# nrf9220_cellrf register map
Vendor: Nordic Semiconductor; Series: nRF92; File version: 1
CPU: CM0 r0p0, little endian, no MPU, no FPU, 2 interrupt priority bits, 33 interrupts
Registers are 32-bit, read-write, reset 0x0 unless marked. A register's access mark holds for its fields unless they carry their own. Offsets are from the block's base; [hi:lo] are bit positions; {n}, {i} and the like mark numbered series; 'fields as' and 'values as' point back to an identical list.

## SX (part 3 of 3) — Ahma SX register map SX register map
Base 0x46147000
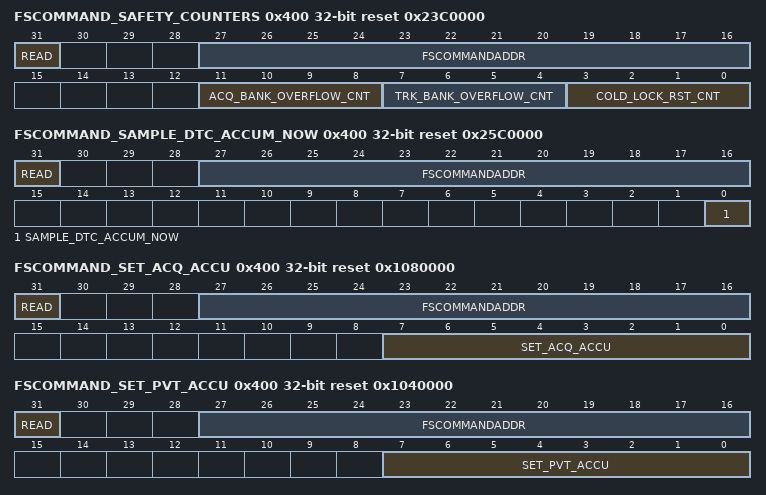
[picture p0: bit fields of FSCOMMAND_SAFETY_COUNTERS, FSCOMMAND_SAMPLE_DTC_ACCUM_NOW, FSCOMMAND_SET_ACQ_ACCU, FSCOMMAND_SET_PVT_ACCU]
0x400 FSCOMMAND_SAFETY_COUNTERS reset 0x23C0000 (alternate view of FSCOMMAND_ANA_ISOLATION) — Send or receive command directly to/from the AdPllLte digital island. Only write to this register when FSASYNCBUSBUSY returns 0
  [31] READ — When 1, a read transaction is initiated. When the event COMPLETETRANS is set, read back this register
  [27:16] FSCOMMANDADDR — Address for the async interface. ALWAYS 0x23C.
    0x23C=SAFETY_COUNTERS_ADDR (ALWAYS 0x23C.)
  [11:8] ACQ_BANK_OVERFLOW_CNT — Number of times there has been ACQ bank overflow since last starting the PLL. Max 15
  [7:4] TRK_BANK_OVERFLOW_CNT — Number of times there has been TRK bank overflow since last starting the PLL. Max 15
  [3:0] COLD_LOCK_RST_CNT — Number of times the cold lock reset safety mechanism has triggered since last starting the PLL. Max 15
0x400 FSCOMMAND_SAMPLE_DTC_ACCUM_NOW reset 0x25C0000 (alternate view of FSCOMMAND_ANA_ISOLATION) — Send or receive command directly to/from the AdPllLte digital island. Only write to this register when FSASYNCBUSBUSY returns 0
  [31] READ — When 1, a read transaction is initiated. When the event COMPLETETRANS is set, read back this register
  [27:16] FSCOMMANDADDR — Address for the async interface. ALWAYS 0x25C.
    0x25C=SAMPLE_DTC_ACCUM_NOW_ADDR (ALWAYS 0x25C.)
  [0] SAMPLE_DTC_ACCUM_NOW — Store the DTC accumulator value now
0x400 FSCOMMAND_SET_ACQ_ACCU reset 0x1080000 (alternate view of FSCOMMAND_ANA_ISOLATION) — Send or receive command directly to/from the AdPllLte digital island. Only write to this register when FSASYNCBUSBUSY returns 0
  [31] READ — When 1, a read transaction is initiated. When the event COMPLETETRANS is set, read back this register
  [27:16] FSCOMMANDADDR — Address for the async interface. ALWAYS 0x108.
    0x108=SET_ACQ_ACCU_ADDR (ALWAYS 0x108.)
  [7:0] SET_ACQ_ACCU — Writing to this register will fill in the ACQ accumulator such that the ACQ control word becomes this value. normAcqMem must be subtracted first
0x400 FSCOMMAND_SET_PVT_ACCU reset 0x1040000 (alternate view of FSCOMMAND_ANA_ISOLATION) — Send or receive command directly to/from the AdPllLte digital island. Only write to this register when FSASYNCBUSBUSY returns 0
  [31] READ — When 1, a read transaction is initiated. When the event COMPLETETRANS is set, read back this register
  [27:16] FSCOMMANDADDR — Address for the async interface. ALWAYS 0x104.
    0x104=SET_PVT_ACCU_ADDR (ALWAYS 0x104.)
  [7:0] SET_PVT_ACCU — Writing to this register will fill in the PVT accumulator such that the PVT control word becomes this value. normPvtMem must be subtracted first
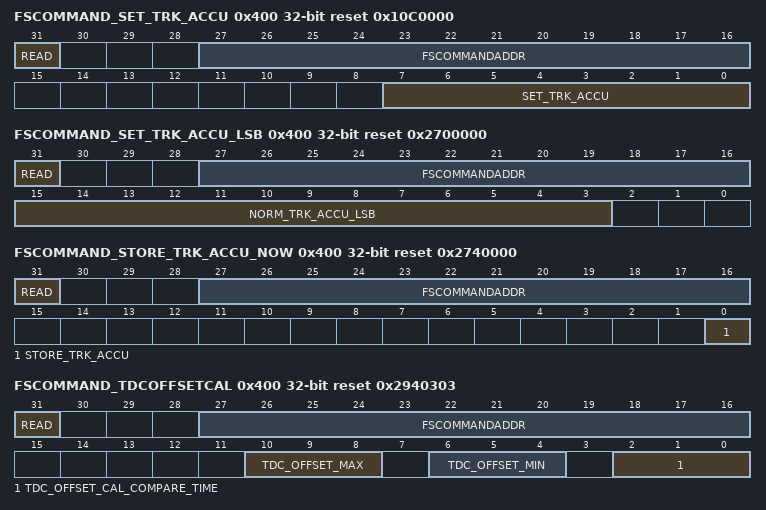
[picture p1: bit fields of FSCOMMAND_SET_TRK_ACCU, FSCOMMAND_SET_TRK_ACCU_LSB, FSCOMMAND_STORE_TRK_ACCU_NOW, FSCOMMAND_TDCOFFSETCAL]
0x400 FSCOMMAND_SET_TRK_ACCU reset 0x10C0000 (alternate view of FSCOMMAND_ANA_ISOLATION) — Send or receive command directly to/from the AdPllLte digital island. Only write to this register when FSASYNCBUSBUSY returns 0
  [31] READ — When 1, a read transaction is initiated. When the event COMPLETETRANS is set, read back this register
  [27:16] FSCOMMANDADDR — Address for the async interface. ALWAYS 0x10C.
    0x10C=SET_TRK_ACCU_ADDR (ALWAYS 0x10C.)
  [7:0] SET_TRK_ACCU — Writing to this register will fill in the TRK accumulator such that the TRK control word becomes this value. normTrkMem must be subtracted first
0x400 FSCOMMAND_SET_TRK_ACCU_LSB reset 0x2700000 (alternate view of FSCOMMAND_ANA_ISOLATION) — Send or receive command directly to/from the AdPllLte digital island. Only write to this register when FSASYNCBUSBUSY returns 0
  [31] READ — When 1, a read transaction is initiated. When the event COMPLETETRANS is set, read back this register
  [27:16] FSCOMMANDADDR — Address for the async interface. ALWAYS 0x270.
    0x270=SET_TRK_ACCU_LSB_ADDR (ALWAYS 0x270.)
  [15:3] NORM_TRK_ACCU_LSB — Sets the LSB in the TRK bank accumulator when explicitly reloading new value
0x400 FSCOMMAND_STORE_TRK_ACCU_NOW reset 0x2740000 (alternate view of FSCOMMAND_ANA_ISOLATION) — Send or receive command directly to/from the AdPllLte digital island. Only write to this register when FSASYNCBUSBUSY returns 0
  [31] READ — When 1, a read transaction is initiated. When the event COMPLETETRANS is set, read back this register
  [27:16] FSCOMMANDADDR — Address for the async interface. ALWAYS 0x274.
    0x274=STORE_TRK_ACCU_NOW_ADDR (ALWAYS 0x274.)
  [0] STORE_TRK_ACCU — Store the full accumulator value in the TRK bank loop filter control
0x400 FSCOMMAND_TDCOFFSETCAL reset 0x2940303 (alternate view of FSCOMMAND_ANA_ISOLATION) — Send or receive command directly to/from the AdPllLte digital island. Only write to this register when FSASYNCBUSBUSY returns 0
  [31] READ — When 1, a read transaction is initiated. When the event COMPLETETRANS is set, read back this register
  [27:16] FSCOMMANDADDR — Address for the async interface. ALWAYS 0x294.
    0x294=TDCOFFSETCAL_ADDR (ALWAYS 0x294.)
  [10:8] TDC_OFFSET_MAX — The maximum TDC offset value for calibration
  [6:4] TDC_OFFSET_MIN — The minimum TDC offset value for calibration
  [2:0] TDC_OFFSET_CAL_COMPARE_TIME — The time to spend on each calibration step in the TDC offset calibration algorithm. Multiply by 32 to get number of clock cycles
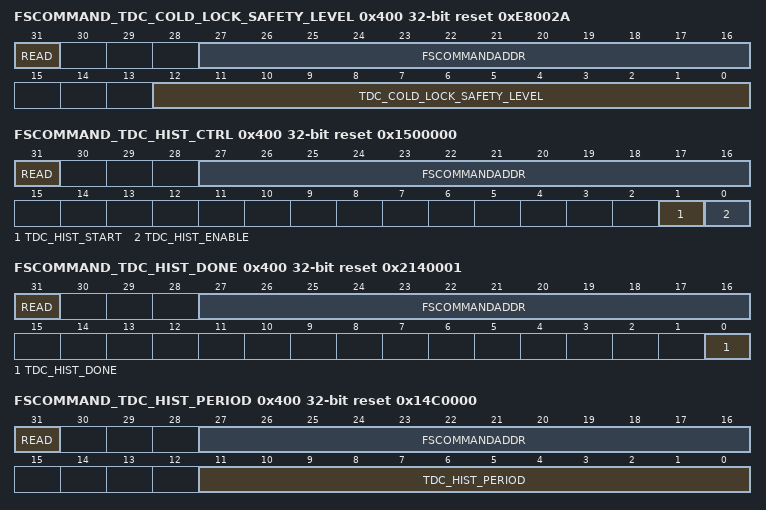
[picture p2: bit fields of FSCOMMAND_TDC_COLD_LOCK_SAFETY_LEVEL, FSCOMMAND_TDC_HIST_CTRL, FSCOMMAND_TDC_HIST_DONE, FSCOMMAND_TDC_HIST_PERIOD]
0x400 FSCOMMAND_TDC_COLD_LOCK_SAFETY_LEVEL reset 0xE8002A (alternate view of FSCOMMAND_ANA_ISOLATION) — Send or receive command directly to/from the AdPllLte digital island. Only write to this register when FSASYNCBUSBUSY returns 0
  [31] READ — When 1, a read transaction is initiated. When the event COMPLETETRANS is set, read back this register
  [27:16] FSCOMMANDADDR — Address for the async interface. ALWAYS 0xE8.
    232=TDC_COLD_LOCK_SAFETY_LEVEL_ADDR (ALWAYS 0xE8.)
  [12:0] TDC_COLD_LOCK_SAFETY_LEVEL — If the TDC output after unwrapping exceeds this level, we will reset the cold lock (w_reset_cold_lock)
0x400 FSCOMMAND_TDC_HIST_CTRL reset 0x1500000 (alternate view of FSCOMMAND_ANA_ISOLATION) — Send or receive command directly to/from the AdPllLte digital island. Only write to this register when FSASYNCBUSBUSY returns 0
  [31] READ — When 1, a read transaction is initiated. When the event COMPLETETRANS is set, read back this register
  [27:16] FSCOMMANDADDR — Address for the async interface. ALWAYS 0x150.
    0x150=TDC_HIST_CTRL_ADDR (ALWAYS 0x150.)
  [1] TDC_HIST_START — Rising edge here will retrigger histogram
  [0] TDC_HIST_ENABLE — Enable histogram module
0x400 FSCOMMAND_TDC_HIST_DONE reset 0x2140001 (alternate view of FSCOMMAND_ANA_ISOLATION) — Send or receive command directly to/from the AdPllLte digital island. Only write to this register when FSASYNCBUSBUSY returns 0
  [31] READ — When 1, a read transaction is initiated. When the event COMPLETETRANS is set, read back this register
  [27:16] FSCOMMANDADDR — Address for the async interface. ALWAYS 0x214.
    0x214=TDC_HIST_DONE_ADDR (ALWAYS 0x214.)
  [0] TDC_HIST_DONE — The result from the histogram
0x400 FSCOMMAND_TDC_HIST_PERIOD reset 0x14C0000 (alternate view of FSCOMMAND_ANA_ISOLATION) — Send or receive command directly to/from the AdPllLte digital island. Only write to this register when FSASYNCBUSBUSY returns 0
  [31] READ — When 1, a read transaction is initiated. When the event COMPLETETRANS is set, read back this register
  [27:16] FSCOMMANDADDR — Address for the async interface. ALWAYS 0x14C.
    0x14C=TDC_HIST_PERIOD_ADDR (ALWAYS 0x14C.)
  [11:0] TDC_HIST_PERIOD — The number of cycles to let the histogram run after having been triggered
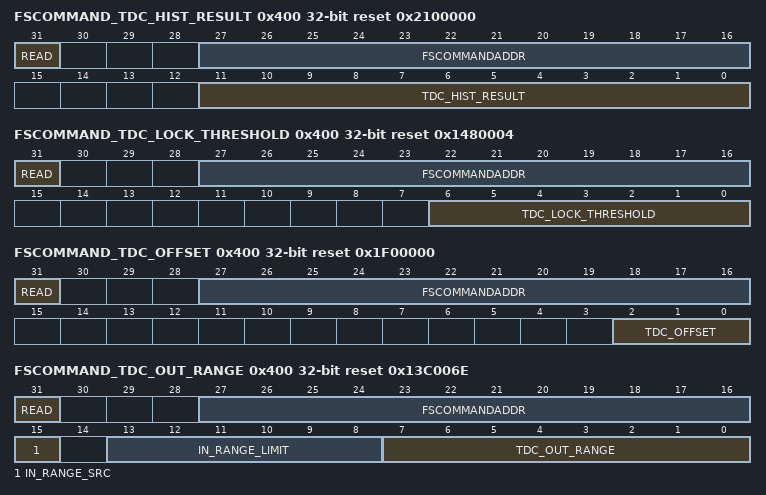
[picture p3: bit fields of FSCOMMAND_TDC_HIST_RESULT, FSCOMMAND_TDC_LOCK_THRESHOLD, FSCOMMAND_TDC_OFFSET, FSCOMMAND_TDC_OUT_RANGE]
0x400 FSCOMMAND_TDC_HIST_RESULT reset 0x2100000 (alternate view of FSCOMMAND_ANA_ISOLATION) — Send or receive command directly to/from the AdPllLte digital island. Only write to this register when FSASYNCBUSBUSY returns 0
  [31] READ — When 1, a read transaction is initiated. When the event COMPLETETRANS is set, read back this register
  [27:16] FSCOMMANDADDR — Address for the async interface. ALWAYS 0x210.
    0x210=TDC_HIST_RESULT_ADDR (ALWAYS 0x210.)
  [11:0] TDC_HIST_RESULT — The result from the histogram
0x400 FSCOMMAND_TDC_LOCK_THRESHOLD reset 0x1480004 (alternate view of FSCOMMAND_ANA_ISOLATION) — Send or receive command directly to/from the AdPllLte digital island. Only write to this register when FSASYNCBUSBUSY returns 0
  [31] READ — When 1, a read transaction is initiated. When the event COMPLETETRANS is set, read back this register
  [27:16] FSCOMMANDADDR — Address for the async interface. ALWAYS 0x148.
    0x148=TDC_LOCK_THRESHOLD_ADDR (ALWAYS 0x148.)
  [6:0] TDC_LOCK_THRESHOLD — The upper threshold for the average TDC value for declaring PLL lock
0x400 FSCOMMAND_TDC_OFFSET reset 0x1F00000 (alternate view of FSCOMMAND_ANA_ISOLATION) — Send or receive command directly to/from the AdPllLte digital island. Only write to this register when FSASYNCBUSBUSY returns 0
  [31] READ — When 1, a read transaction is initiated. When the event COMPLETETRANS is set, read back this register
  [27:16] FSCOMMANDADDR — Address for the async interface. ALWAYS 0x1F0.
    0x1F0=TDC_OFFSET_ADDR (ALWAYS 0x1F0.)
  [2:0] TDC_OFFSET — Read the current TDC_OFFSET setting
0x400 FSCOMMAND_TDC_OUT_RANGE reset 0x13C006E (alternate view of FSCOMMAND_ANA_ISOLATION) — Send or receive command directly to/from the AdPllLte digital island. Only write to this register when FSASYNCBUSBUSY returns 0
  [31] READ — When 1, a read transaction is initiated. When the event COMPLETETRANS is set, read back this register
  [27:16] FSCOMMANDADDR — Address for the async interface. ALWAYS 0x13C.
    0x13C=TDC_OUT_RANGE_ADDR (ALWAYS 0x13C.)
  [15] IN_RANGE_SRC — If 0, use raw TDC as input. If 1, use unwrapped TDC as input.
  [13:8] IN_RANGE_LIMIT — The unwrapped TDC value needs to be within +- this value before the kDTC estimator can be turned on. If 0, fall back to backwards compatible behaviour where the field TDC_OUT_RANGE is used instead
  [7:0] TDC_OUT_RANGE — The maximum value in the thermometric to binary decoder in TdcReadout
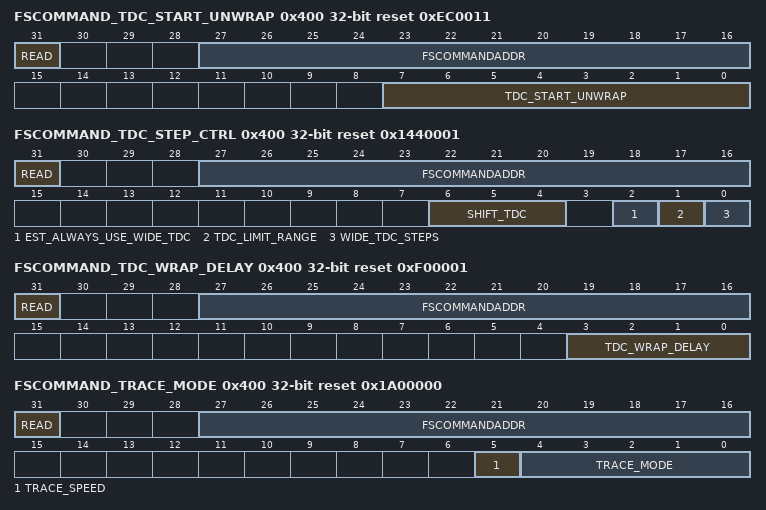
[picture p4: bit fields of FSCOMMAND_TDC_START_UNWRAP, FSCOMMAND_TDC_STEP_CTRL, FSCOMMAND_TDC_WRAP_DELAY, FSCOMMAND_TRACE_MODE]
0x400 FSCOMMAND_TDC_START_UNWRAP reset 0xEC0011 (alternate view of FSCOMMAND_ANA_ISOLATION) — Send or receive command directly to/from the AdPllLte digital island. Only write to this register when FSASYNCBUSBUSY returns 0
  [31] READ — When 1, a read transaction is initiated. When the event COMPLETETRANS is set, read back this register
  [27:16] FSCOMMANDADDR — Address for the async interface. ALWAYS 0xEC.
    236=TDC_START_UNWRAP_ADDR (ALWAYS 0xEC.)
  [7:0] TDC_START_UNWRAP — Under which gear level to start TDC unwrap
0x400 FSCOMMAND_TDC_STEP_CTRL reset 0x1440001 (alternate view of FSCOMMAND_ANA_ISOLATION) — Send or receive command directly to/from the AdPllLte digital island. Only write to this register when FSASYNCBUSBUSY returns 0
  [31] READ — When 1, a read transaction is initiated. When the event COMPLETETRANS is set, read back this register
  [27:16] FSCOMMANDADDR — Address for the async interface. ALWAYS 0x144.
    0x144=TDC_STEP_CTRL_ADDR (ALWAYS 0x144.)
  [6:4] SHIFT_TDC — Signed value for shifting the TDC code being used as center up and down +-2
  [2] EST_ALWAYS_USE_WIDE_TDC — If 1, then we always use the wideTdcSteps for the estimators (estkdtc, estdutycycle) even when narrow TDC LSBs for the main PLL loop
  [1] TDC_LIMIT_RANGE — If set to 1, we ignore the 2 outermost values of the TDC on both sides
  [0] WIDE_TDC_STEPS — Only use every second bit in the output word from FS_TDC - effectively making the step size / LSB twice as big
0x400 FSCOMMAND_TDC_WRAP_DELAY reset 0xF00001 (alternate view of FSCOMMAND_ANA_ISOLATION) — Send or receive command directly to/from the AdPllLte digital island. Only write to this register when FSASYNCBUSBUSY returns 0
  [31] READ — When 1, a read transaction is initiated. When the event COMPLETETRANS is set, read back this register
  [27:16] FSCOMMANDADDR — Address for the async interface. ALWAYS 0xF0.
    240=TDC_WRAP_DELAY_ADDR (ALWAYS 0xF0.)
  [3:0] TDC_WRAP_DELAY — The number of cycles x 128 to wait before we set o_in_tdc_range in TdcReadout
0x400 FSCOMMAND_TRACE_MODE reset 0x1A00000 (alternate view of FSCOMMAND_ANA_ISOLATION) — Send or receive command directly to/from the AdPllLte digital island. Only write to this register when FSASYNCBUSBUSY returns 0
  [31] READ — When 1, a read transaction is initiated. When the event COMPLETETRANS is set, read back this register
  [27:16] FSCOMMANDADDR — Address for the async interface. ALWAYS 0x1A0.
    0x1A0=TRACE_MODE_ADDR (ALWAYS 0x1A0.)
  [5] TRACE_SPEED — Set tracing speed. 0: 16MHz, 1: 32MHz
  [4:0] TRACE_MODE — Set tracing mode
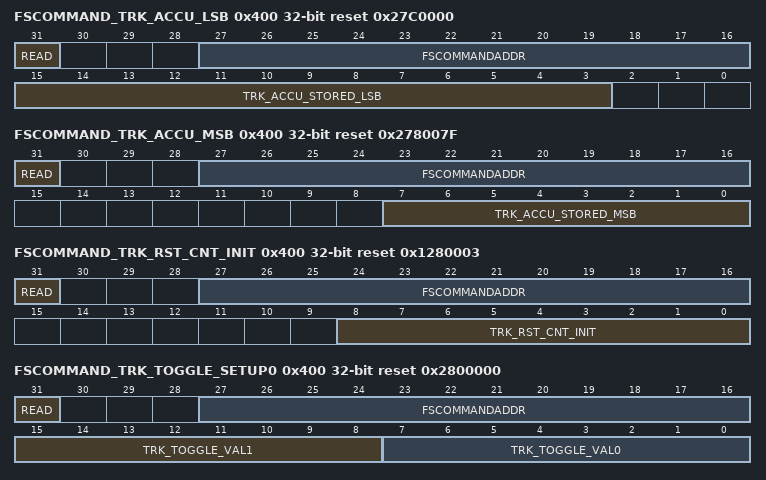
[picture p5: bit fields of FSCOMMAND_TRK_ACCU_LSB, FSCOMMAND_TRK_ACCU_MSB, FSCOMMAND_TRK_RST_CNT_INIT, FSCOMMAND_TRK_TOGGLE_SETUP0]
0x400 FSCOMMAND_TRK_ACCU_LSB reset 0x27C0000 (alternate view of FSCOMMAND_ANA_ISOLATION) — Send or receive command directly to/from the AdPllLte digital island. Only write to this register when FSASYNCBUSBUSY returns 0
  [31] READ — When 1, a read transaction is initiated. When the event COMPLETETRANS is set, read back this register
  [27:16] FSCOMMANDADDR — Address for the async interface. ALWAYS 0x27C.
    0x27C=TRK_ACCU_LSB_ADDR (ALWAYS 0x27C.)
  [15:3] TRK_ACCU_STORED_LSB — When storing the full accumulator value, the LSBs will be found here
0x400 FSCOMMAND_TRK_ACCU_MSB reset 0x278007F (alternate view of FSCOMMAND_ANA_ISOLATION) — Send or receive command directly to/from the AdPllLte digital island. Only write to this register when FSASYNCBUSBUSY returns 0
  [31] READ — When 1, a read transaction is initiated. When the event COMPLETETRANS is set, read back this register
  [27:16] FSCOMMANDADDR — Address for the async interface. ALWAYS 0x278.
    0x278=TRK_ACCU_MSB_ADDR (ALWAYS 0x278.)
  [7:0] TRK_ACCU_STORED_MSB — When storing the full accumulator value, the MSBs will be found here
0x400 FSCOMMAND_TRK_RST_CNT_INIT reset 0x1280003 (alternate view of FSCOMMAND_ANA_ISOLATION) — Send or receive command directly to/from the AdPllLte digital island. Only write to this register when FSASYNCBUSBUSY returns 0
  [31] READ — When 1, a read transaction is initiated. When the event COMPLETETRANS is set, read back this register
  [27:16] FSCOMMANDADDR — Address for the async interface. ALWAYS 0x128.
    0x128=TRK_RST_CNT_INIT_ADDR (ALWAYS 0x128.)
  [8:0] TRK_RST_CNT_INIT — Delay reset of normTrk this number of cycles
0x400 FSCOMMAND_TRK_TOGGLE_SETUP0 reset 0x2800000 (alternate view of FSCOMMAND_ANA_ISOLATION) — Send or receive command directly to/from the AdPllLte digital island. Only write to this register when FSASYNCBUSBUSY returns 0
  [31] READ — When 1, a read transaction is initiated. When the event COMPLETETRANS is set, read back this register
  [27:16] FSCOMMANDADDR — Address for the async interface. ALWAYS 0x280.
    0x280=TRK_TOGGLE_SETUP0_ADDR (ALWAYS 0x280.)
  [15:8] TRK_TOGGLE_VAL1 — The second toggle value if toggle mode is enabled (Toggle mode gets enabled if toggleVal3 != 0)
  [7:0] TRK_TOGGLE_VAL0 — The first toggle value if toggle mode is enabled (Toggle mode gets enabled if toggleVal3 != 0)
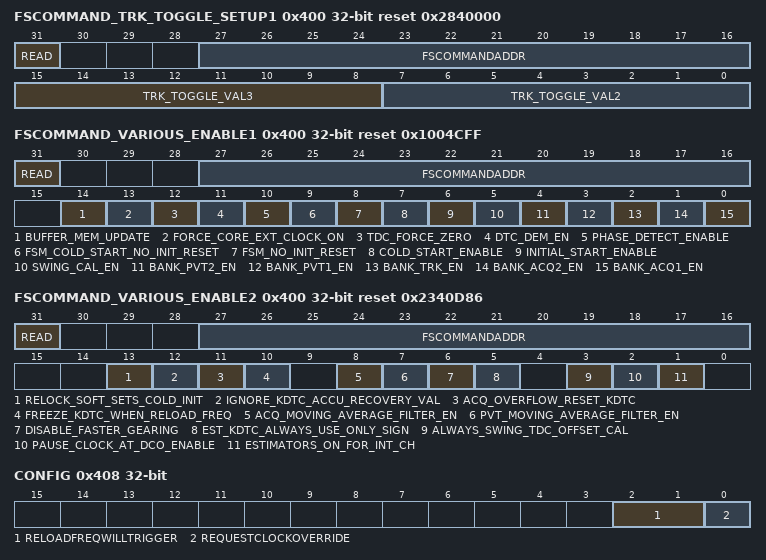
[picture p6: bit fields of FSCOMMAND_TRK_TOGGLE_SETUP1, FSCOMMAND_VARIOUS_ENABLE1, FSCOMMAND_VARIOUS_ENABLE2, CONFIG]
0x400 FSCOMMAND_TRK_TOGGLE_SETUP1 reset 0x2840000 (alternate view of FSCOMMAND_ANA_ISOLATION) — Send or receive command directly to/from the AdPllLte digital island. Only write to this register when FSASYNCBUSBUSY returns 0
  [31] READ — When 1, a read transaction is initiated. When the event COMPLETETRANS is set, read back this register
  [27:16] FSCOMMANDADDR — Address for the async interface. ALWAYS 0x284.
    0x284=TRK_TOGGLE_SETUP1_ADDR (ALWAYS 0x284.)
  [15:8] TRK_TOGGLE_VAL3 — The fourth toggle value if toggle mode is enabled (Toggle mode gets enabled if toggleVal3 != 0)
  [7:0] TRK_TOGGLE_VAL2 — The third toggle value if toggle mode is enabled (Toggle mode gets enabled if toggleVal3 != 0)
0x400 FSCOMMAND_VARIOUS_ENABLE1 reset 0x1004CFF (alternate view of FSCOMMAND_ANA_ISOLATION) — Send or receive command directly to/from the AdPllLte digital island. Only write to this register when FSASYNCBUSBUSY returns 0
  [31] READ — When 1, a read transaction is initiated. When the event COMPLETETRANS is set, read back this register
  [27:16] FSCOMMANDADDR — Address for the async interface. ALWAYS 0x100.
    0x100=VARIOUS_ENABLE1_ADDR (ALWAYS 0x100.)
  [14] BUFFER_MEM_UPDATE — When 1, we will wait until the uni trigger arrives before applying changes to normPvtMem, normAcqMem and normTrkMem
  [13] FORCE_CORE_EXT_CLOCK_ON — By default the clock to AdPllCoreExt is stopped when the state machine is not active. If setting this to 1, the clock is always on
  [12] TDC_FORCE_ZERO — Force the binary TDC output from tdcRealign to the TRK bank control to zero. This basically opens up the loop
  [11] DTC_DEM_EN — Connected directly to the output signal 'dtcDemEn'
  [10] PHASE_DETECT_ENABLE — Selects whether phase detect of the output from the counter should be enabled or not
  [9] FSM_COLD_START_NO_INIT_RESET — Backdoor which prevents r_cold_start from being set low when receiving a channel switch trigger while being in the TRK state
  [8] FSM_NO_INIT_RESET — Backdoor which prevents r_initial_start from being set low when receiving a channel switch trigger while being in the TRK state
  [7] COLD_START_ENABLE — Whether to enable 'cold start' or not (whenever retriggering startup). 'cold start' initializes even more. During a cold start, phaseSelect randomization is forced on
  [6] INITIAL_START_ENABLE — Whether to enable 'initial start' or not (whenever retriggering startup). 'initial start' re-initializes EstKdtc
  [5] SWING_CAL_EN — Include swing calibration during startup
  [4] BANK_PVT2_EN — Enable recalibration of the PVT bank after swing calibration
  [3] BANK_PVT1_EN — Enable the PVT bank
  [2] BANK_TRK_EN — Enable the TRK bank
  [1] BANK_ACQ2_EN — Enable recalibration of the ACQ bank after swing calibration
  [0] BANK_ACQ1_EN — Enable the ACQ bank
0x400 FSCOMMAND_VARIOUS_ENABLE2 reset 0x2340D86 (alternate view of FSCOMMAND_ANA_ISOLATION) — Send or receive command directly to/from the AdPllLte digital island. Only write to this register when FSASYNCBUSBUSY returns 0
  [31] READ — When 1, a read transaction is initiated. When the event COMPLETETRANS is set, read back this register
  [27:16] FSCOMMANDADDR — Address for the async interface. ALWAYS 0x234.
    0x234=VARIOUS_ENABLE2_ADDR (ALWAYS 0x234.)
  [13] RELOCK_SOFT_SETS_COLD_INIT — Always execute cold start init when using trigger uniTriggerRelockBackToAcq or uniTriggerRelockBackToTrk.
  [12] IGNORE_KDTC_ACCU_RECOVERY_VAL — If set to 1, we do not use the recovery value of the kDTC accumulator captured during the first lock after power-up.
  [11] ACQ_OVERFLOW_RESET_KDTC — When the ACQ bank overflows, we reset the KDTC estimator to the middle
  [10] FREEZE_KDTC_WHEN_RELOAD_FREQ — When loading new frequency, we temporarily freeze the kDTC estimator. This is mostly interesting when staying in TRK bank state, because when going back to PVT or ACQ state, the kDTC estimator is anyway disabled for a while.
  [8] ACQ_MOVING_AVERAGE_FILTER_EN — Enable the moving average filter in the ACQ bank control
  [7] PVT_MOVING_AVERAGE_FILTER_EN — Enable the moving average filter in the PVT bank control
  [6] DISABLE_FASTER_GEARING — For adding backwards compatibility: When requesting frequency reload together with back-to-TRK, the gearing happens twice as fast as during normal PLL startup if this register is not set. It also happens twice as fast when loading a phase change with the PHASE_CHANGE register
  [5] EST_KDTC_ALWAYS_USE_ONLY_SIGN — If 1, estkdtc only uses sign also outside packet
  [3] ALWAYS_SWING_TDC_OFFSET_CAL — If 1, swing and TDC offet calibration is performed every time new frequency is triggered with full start
  [2] PAUSE_CLOCK_AT_DCO_ENABLE — If 1, when DCO gets enabled we temporarily stop the clock since there is a glitch-risk
  [1] ESTIMATORS_ON_FOR_INT_CH — When 0, estkdtc and estdutycycle is not active for integer channels
0x404 ENABLE — Enable AdPllCompanionLte IP
  [0] ENABLE — Enable the IP
    0=Reset (IP core synchronous reset); 1=Enable
0x408 CONFIG — Common configurations of AdPllCompanionLte
  [2:1] RELOADFREQWILLTRIGGER — Set up the specific unitrigger to be activated when a frequency reload request is made through TASKS_RELOADFREQINTERNAL
    0=changeFreq_restart (RF frequency will be switched, and the state machine will start from the first state); 1=changeFreq_backToACQ (RF frequency will be switched and the state machine will go back to the ACQ2 state); 2=changeFreq_backToFastTRK (RF frequency will be switched and the TRK bank will switch temporarily to the fastest gear); 3=changeFreq_TRK (RF frequency will be reloaded while the loop is operating as normal)
  [0] REQUESTCLOCKOVERRIDE — Force requesting clock
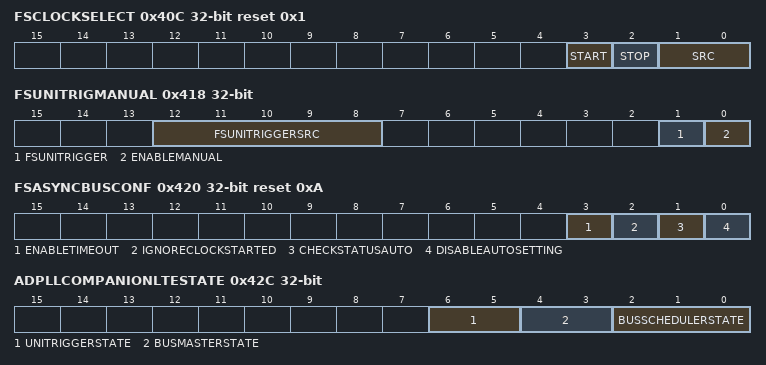
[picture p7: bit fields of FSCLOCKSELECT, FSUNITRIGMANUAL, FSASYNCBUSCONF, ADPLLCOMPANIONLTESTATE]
0x40C FSCLOCKSELECT reset 0x1 — Back-up solution: Set the clock source for the AdPllLte digital island
  [3] START — Start the clock again after the AdPllLte island stops the clock by its own
  [2] STOP — Force-stopping the clock internally in the AdPllLte island
  [1:0] SRC — Select which clock source to be used in the AdPllLte digital island. Effective only when automatic clock switching is disabled in the AdPllLte digital island. 2'b00: ck64MCore, 2'b01: ckRetimed, 2'b10: ckRef
0x410 CLOCKSTARTED ro — Status bit indicating whether the clock has started in AdPllLte digital island
  [0] CLOCKSTARTED — Whether the clock is running or or not
0x414 FSUNITRIGGERCONF reset 0x1 — Some special settings for the unitrigger configuration
  [0] ENABLETIMEOUT — Back-up solution: Enable timeouts for unitrigger handshakes
0x418 FSUNITRIGMANUAL — Manual control of the uni trigger signals.
  [12:8] FSUNITRIGGERSRC — The fsUniTriggerCalSrc signal when using manual control
  [1] FSUNITRIGGER — The fsUniTrigger signal when using manual control
  [0] ENABLEMANUAL — Enable manual control
0x41C FSUNITRIGGERBUSY ro — Status bit indicating whether the unitrigger is currently busy or not
  [0] UNITRIGGERBUSY — Whether the unitrigger is currently busy or not.
0x420 FSASYNCBUSCONF reset 0xA — Some special settings for the asynchronous bus configuration
  [3] ENABLETIMEOUT — Back-up solution: Enable timeouts for async bus handshakes
  [2] IGNORECLOCKSTARTED — The bus scheduler will not wait for AdPllLte to say clockStarted
  [1] CHECKSTATUSAUTO — When set to 1, monitor the transactions while in auto-send mode. Upon the first erroneous transaction, halt the state machine immediately
  [0] DISABLEAUTOSETTING — Do not send settings at the beginning to AdPllLte
0x424 FSASYNCBUSBUSY ro reset 0x1 — Status bit indicating whether the bus is currently busy or not
  [0] FSASYNCBUSBUSY — Whether the bus is currently busy or not
0x428 TRACING — Enable tracing from AdPllLte
  [0] ENABLE
0x42C ADPLLCOMPANIONLTESTATE ro — State in the AdPllCompanionLte state machines
  [6:5] UNITRIGGERSTATE — The state of the state machine inside unitrigger
  [4:3] BUSMASTERSTATE — The state of the state machine inside async bus master
  [2:0] BUSSCHEDULERSTATE — The state of the state machine which sends commands automatically at startup
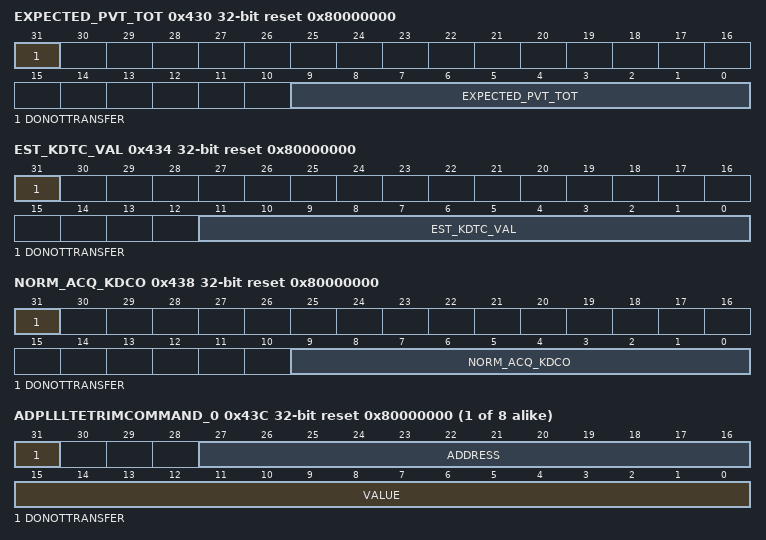
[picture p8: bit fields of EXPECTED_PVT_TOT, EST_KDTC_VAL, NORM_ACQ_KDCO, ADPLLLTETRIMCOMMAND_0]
0x430 EXPECTED_PVT_TOT reset 0x80000000 — This value is written to the AdPllLte when powering up the digital island. Can be reset with SOFTRESET
  [31] DONOTTRANSFER — When 1, we do not transfer this word to AdPllLte at power up
  [9:0] EXPECTED_PVT_TOT — The ratio between PVT and the total cap ratio. Used in TdcReadout
0x434 EST_KDTC_VAL reset 0x80000000 — This value is written to the AdPllLte when powering up the digital island. Can be reset with SOFTRESET
  [31] DONOTTRANSFER — When 1, we do not transfer this word to AdPllLte at power up
  [11:0] EST_KDTC_VAL — The estimated kDTC value in typical
0x438 NORM_ACQ_KDCO reset 0x80000000 — This value is written to the AdPllLte when powering up the digital island. Can be reset with SOFTRESET
  [31] DONOTTRANSFER — When 1, we do not transfer this word to AdPllLte at power up
  [9:0] NORM_ACQ_KDCO — Calibration value for the PLL
{0x43C+4i} ADPLLLTETRIMCOMMAND_{i} reset 0x80000000 (i=0..7) — This value is written to the AdPllLte when powering up the digital island. Can be reset with SOFTRESET.
  [31] DONOTTRANSFER — When 1, we do not transfer this word to AdPllLte at power up
  [27:16] ADDRESS — The address of the digital island to write to
  [15:0] VALUE — The value to be written the register in the digital island
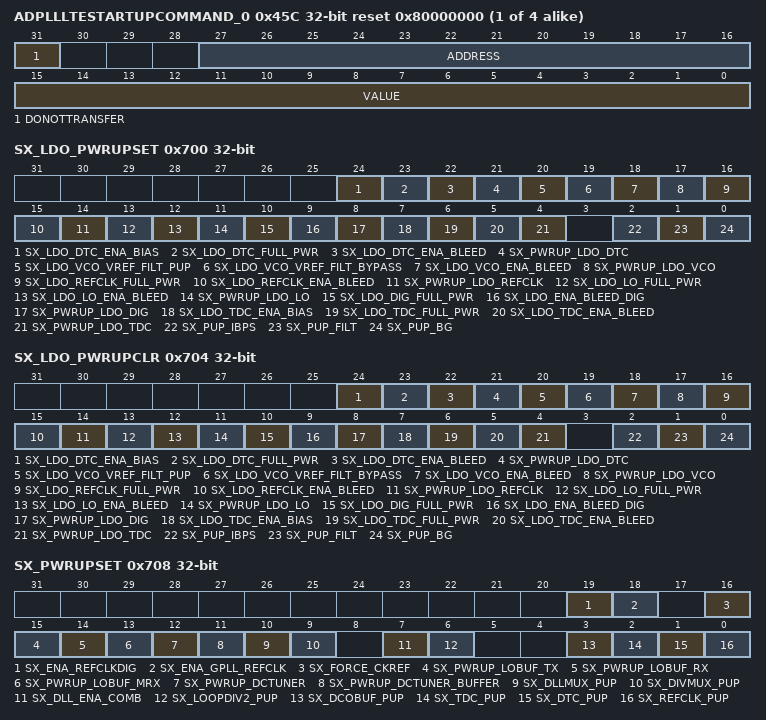
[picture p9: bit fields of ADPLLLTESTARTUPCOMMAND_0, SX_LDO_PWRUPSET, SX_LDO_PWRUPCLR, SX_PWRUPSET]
{0x45C+4i} ADPLLLTESTARTUPCOMMAND_{i} reset 0x80000000 (i=0..3) — This value is written to the AdPllLte when powering up the digital island. Can be reset with SOFTRESET
  fields as ADPLLLTETRIMCOMMAND_0
0x500 DMAENABLE — Enable DMA
  [0] ENABLE
0x504 DMAPTR — Memory address to where in memory the DMA will transfer the trace data
  [15:0] PTR — Data pointer
0x508 DMAMAXCNT — Maximum number of bytes that should be transferred via DMA
  [15:0] MAXCNT
0x50C DMAAMOUNT ro — Total number of bytes transferred via DMA
  [15:0] AMOUNT
0x510 DMACURRENTAMOUNT ro — Number of bytes transferred so far via DMA
  [15:0] CURRENTAMOUNT
0x514 DMATERMONAHBERROR — Select if DMA should terminate on AHB bus error
  [0] ENABLE — Terminates if there is an error from ahbHResp
0x518 DMAAHBERRORADDR ro — Read the AHB address causing an error response on the AHB bus
  [15:0] ADDR — Failing memory address on AHB bus
0x51C DMAMODE reset 0x1 — Configure DMA low power operation
  [0] LPOP — Enable low-power or low-latency operation
    0=Low-latency operation; 1=Low-power operation
0x700 SX_LDO_PWRUPSET write-1-sets — SX LDO power power up register
  [all] fields
    1=SET (Unspecified); 0=NoEffect (Unspecified)
  [24] SX_LDO_DTC_ENA_BIAS — LDO bias power up
  [23] SX_LDO_DTC_FULL_PWR — LDO full power
  [22] SX_LDO_DTC_ENA_BLEED — LDO bleed
  [21] SX_PWRUP_LDO_DTC — LDO power up
  [20] SX_LDO_VCO_VREF_FILT_PUP — Enable VREF voltage and its selection logic
  [19] SX_LDO_VCO_VREF_FILT_BYPASS — Bypass large R in VREF RC filter
  [18] SX_LDO_VCO_ENA_BLEED — LDO bleed
  [17] SX_PWRUP_LDO_VCO — LDO power up
  [16] SX_LDO_REFCLK_FULL_PWR — LDO full power
  [15] SX_LDO_REFCLK_ENA_BLEED — LDO bleed
  [14] SX_PWRUP_LDO_REFCLK — LDO power up
  [13] SX_LDO_LO_FULL_PWR — LDO full power
  [12] SX_LDO_LO_ENA_BLEED — LDO bleed
  [11] SX_PWRUP_LDO_LO — LDO power up
  [10] SX_LDO_DIG_FULL_PWR — LDO full power
  [9] SX_LDO_ENA_BLEED_DIG — LDO bleed
  [8] SX_PWRUP_LDO_DIG — LDO power up
  [7] SX_LDO_TDC_ENA_BIAS — LDO bias power up
  [6] SX_LDO_TDC_FULL_PWR — LDO full power
  [5] SX_LDO_TDC_ENA_BLEED — LDO bleed
  [4] SX_PWRUP_LDO_TDC — LDO power up
  [2] SX_PUP_IBPS — Bias power up
  [1] SX_PUP_FILT — Bias power up
  [0] SX_PUP_BG — Bias power up
0x704 SX_LDO_PWRUPCLR write-1-clears — SX LDO power power down register
  [all] fields
    1=CLR (Unspecified); 0=NoEffect (Unspecified)
  [24] SX_LDO_DTC_ENA_BIAS — LDO bias power down
  [23] SX_LDO_DTC_FULL_PWR — LDO full power
  [22] SX_LDO_DTC_ENA_BLEED — LDO bleed
  [21] SX_PWRUP_LDO_DTC — LDO power down
  [20] SX_LDO_VCO_VREF_FILT_PUP — Enable VREF voltage and its selection logic
  [19] SX_LDO_VCO_VREF_FILT_BYPASS — Bypass large R in VREF RC filter
  [18] SX_LDO_VCO_ENA_BLEED — LDO bleed
  [17] SX_PWRUP_LDO_VCO — LDO power down
  [16] SX_LDO_REFCLK_FULL_PWR — LDO full power
  [15] SX_LDO_REFCLK_ENA_BLEED — LDO bleed
  [14] SX_PWRUP_LDO_REFCLK — LDO power down
  [13] SX_LDO_LO_FULL_PWR — LDO full power
  [12] SX_LDO_LO_ENA_BLEED — LDO bleed
  [11] SX_PWRUP_LDO_LO — LDO power down
  [10] SX_LDO_DIG_FULL_PWR — LDO full power
  [9] SX_LDO_ENA_BLEED_DIG — LDO bleed
  [8] SX_PWRUP_LDO_DIG — LDO power down
  [7] SX_LDO_TDC_ENA_BIAS — LDO bias power down
  [6] SX_LDO_TDC_FULL_PWR — LDO full power
  [5] SX_LDO_TDC_ENA_BLEED — LDO bleed
  [4] SX_PWRUP_LDO_TDC — LDO power down
  [2] SX_PUP_IBPS — Bias power down
  [1] SX_PUP_FILT — Bias power down
  [0] SX_PUP_BG — Bias power down
0x708 SX_PWRUPSET write-1-sets — SX power up register
  [all] fields
    1=SET (Unspecified); 0=NoEffect (Unspecified)
  [19] SX_ENA_REFCLKDIG — Power up - not used
  [18] SX_ENA_GPLL_REFCLK — Power up
  [16] SX_FORCE_CKREF — Power up
  [15] SX_PWRUP_LOBUF_TX — Power up
  [14] SX_PWRUP_LOBUF_RX — Power up
  [13] SX_PWRUP_LOBUF_MRX — Power up
  [12] SX_PWRUP_DCTUNER — Power up
  [11] SX_PWRUP_DCTUNER_BUFFER — Power up
  [10] SX_DLLMUX_PUP — Power up
  [9] SX_DIVMUX_PUP — Power up
  [7] SX_DLL_ENA_COMB — Power up
  [6] SX_LOOPDIV2_PUP — Power up
  [3] SX_DCOBUF_PUP — Power up
  [2] SX_TDC_PUP — Power up
  [1] SX_DTC_PUP — Power up
  [0] SX_REFCLK_PUP — Power up
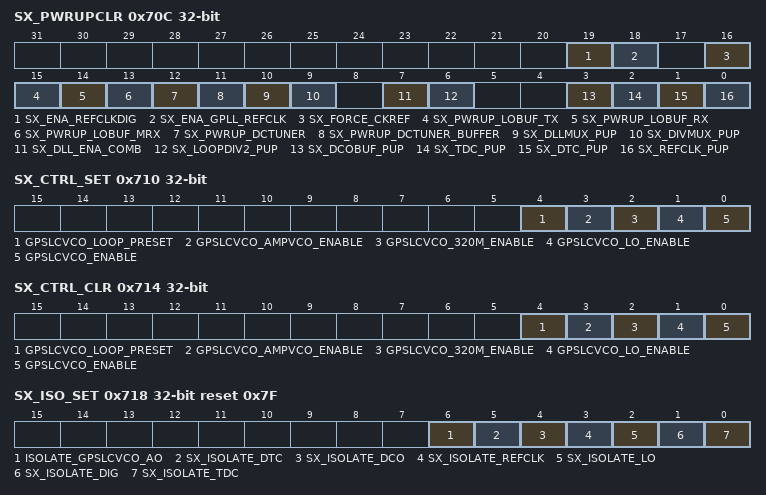
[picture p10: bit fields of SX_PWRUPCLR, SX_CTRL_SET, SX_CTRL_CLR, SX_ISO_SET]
0x70C SX_PWRUPCLR write-1-clears — SX power down register
  [all] fields
    1=CLR (Unspecified); 0=NoEffect (Unspecified)
  [19] SX_ENA_REFCLKDIG — Power down - not used
  [18] SX_ENA_GPLL_REFCLK — Power down
  [16] SX_FORCE_CKREF — Power down
  [15] SX_PWRUP_LOBUF_TX — Power down
  [14] SX_PWRUP_LOBUF_RX — Power down
  [13] SX_PWRUP_LOBUF_MRX — Power down
  [12] SX_PWRUP_DCTUNER — Power down
  [11] SX_PWRUP_DCTUNER_BUFFER — Power down
  [10] SX_DLLMUX_PUP — Power down
  [9] SX_DIVMUX_PUP — Power down
  [7] SX_DLL_ENA_COMB — Power down
  [6] SX_LOOPDIV2_PUP — Power down
  [3] SX_DCOBUF_PUP — Power down
  [2] SX_TDC_PUP — Power down
  [1] SX_DTC_PUP — Power down
  [0] SX_REFCLK_PUP — Power down
0x710 SX_CTRL_SET write-1-sets — SX control set register
  [all] fields
    1=SET (Unspecified); 0=NoEffect (Unspecified)
  [4] GPSLCVCO_LOOP_PRESET — GPSLCVCO loop preset active
  [3] GPSLCVCO_AMPVCO_ENABLE — LCVCO ampitude meas on
  [2] GPSLCVCO_320M_ENABLE — LCVCO ADC CLK enable on
  [1] GPSLCVCO_LO_ENABLE — LCVCO LO enable on
  [0] GPSLCVCO_ENABLE — LCVCO power up
0x714 SX_CTRL_CLR write-1-clears — SX control clr register
  [all] fields
    1=CLR (Unspecified); 0=NoEffect (Unspecified)
  [4] GPSLCVCO_LOOP_PRESET — GPSLCVCO loop preset off
  [3] GPSLCVCO_AMPVCO_ENABLE — LCVCO ampitude meas off
  [2] GPSLCVCO_320M_ENABLE — LCVCO ADC CLK enable off
  [1] GPSLCVCO_LO_ENABLE — LCVCO LO enable off
  [0] GPSLCVCO_ENABLE — LCVCO power down
0x718 SX_ISO_SET reset 0x7F write-1-sets — SX isolation set register
  [all] fields
    1=SET (Unspecified); 0=NoEffect (Unspecified)
  [6] ISOLATE_GPSLCVCO_AO — Tie control signals in the AVDD_GPSLCVCO_0V8 domain to AVSS
  [5] SX_ISOLATE_DTC — Tie control signals in the AVDD_DTC domain to AVSS
  [4] SX_ISOLATE_DCO — Tie control signals in the AVDD_0V8_DCO domain to AVSS
  [3] SX_ISOLATE_REFCLK — Tie control signals in the AVDD_0V8_REFCLK domain to AVSS
  [2] SX_ISOLATE_LO — Tie control signals in the AVDD_0V8_LO domain to AVSS
  [1] SX_ISOLATE_DIG — Tie control signals in the AVDD_0V8_DIG domain to AVSS
  [0] SX_ISOLATE_TDC — Tie control signals in the AVDD_0V8_TDC domain to AVSS
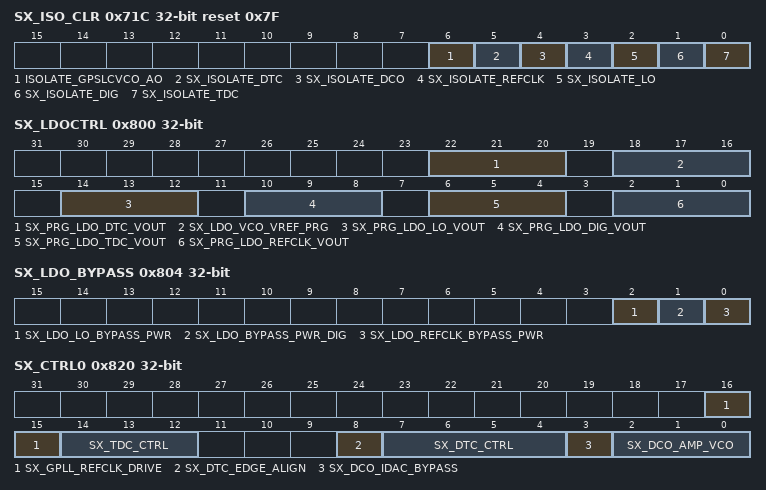
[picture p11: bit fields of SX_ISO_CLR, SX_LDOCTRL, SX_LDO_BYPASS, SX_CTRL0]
0x71C SX_ISO_CLR reset 0x7F write-1-clears — SX isolation clr register
  [all] fields
    1=CLR (Unspecified); 0=NoEffect (Unspecified)
  [6] ISOLATE_GPSLCVCO_AO — Release control signals in the AVDD_GPSLCVCO_0V8 domain from AVSS
  [5] SX_ISOLATE_DTC — Release control signals in the AVDD_DTC_0V8 domain from AVSS
  [4] SX_ISOLATE_DCO — Release control signals in the AVDD_0V8_DCO domain from AVSS
  [3] SX_ISOLATE_REFCLK — Release control signals in the AVDD_0V8_REFCLK domain from AVSS
  [2] SX_ISOLATE_LO — Release control signals in the AVDD_0V8_LO domain from AVSS
  [1] SX_ISOLATE_DIG — Release control signals in the AVDD_0V8_DIG domain from AVSS
  [0] SX_ISOLATE_TDC — Release control signals in the AVDD_0V8_TDC domain from AVSS
0x800 SX_LDOCTRL — SX LDO control
  [22:20] SX_PRG_LDO_DTC_VOUT — Programmable output voltage of the VCO LDO
    0=800mV (default); 1=825mV (Unspecified); 2=850mV (Unspecified); 3=900mV (Unspecified); 7=750mV (Unspecified); 6=700mV (Unspecified); 5=650mV (Unspecified); 4=600mV (Unspecified)
  [18:16] SX_LDO_VCO_VREF_PRG — Programmable output voltage of the VCO LDO
    values as SX_PRG_LDO_DTC_VOUT
  [14:12] SX_PRG_LDO_LO_VOUT — Programmable output voltage of the LO LDO
    0=800mV (default); 1=825mV (Unspecified); 2=850mV (Unspecified); 3=875mV (Unspecified); 7=775mV (Unspecified); 6=750mV (Unspecified); 5=725mV (Unspecified); 4=700mV (Unspecified)
  [10:8] SX_PRG_LDO_DIG_VOUT — Programmable output voltage of the DIG LDO
    values as SX_PRG_LDO_DTC_VOUT
  [6:4] SX_PRG_LDO_TDC_VOUT — Programmable output voltage of the TDC LDO
    values as SX_PRG_LDO_DTC_VOUT
  [2:0] SX_PRG_LDO_REFCLK_VOUT — Programmable output voltage of the REFCLK LDO
    values as SX_PRG_LDO_DTC_VOUT
0x804 SX_LDO_BYPASS
  [all] fields
    1=Bypass (don't use); 0=NoEffect (default)
  [2] SX_LDO_LO_BYPASS_PWR — Bypasses the output PMOS in the LO LDO
  [1] SX_LDO_BYPASS_PWR_DIG — Bypasses the output PMOS in the DIG LDO
  [0] SX_LDO_REFCLK_BYPASS_PWR — Bypasses the output PMOS in the REFCLK LDO
0x808 SX_R_TRIM — SX R trimming control
  [3:0] SX_IBPS_R_TRIM — Trimming control word for 10uA IBPS reference bias current
    0=typ (default, twos complement coding); 8=min (Unspecified); 7=max (Unspecified)
0x80C SX_SWRESET
  [0] ARSTFS_N — General asynchronous reset
    1=Reset (Unspecified); 0=NoReset (Unspecified)
0x810 SX_FREQ
  [29:0] FS_FREQ — Frequency control word
    0=minFreq (Unspecified)
0x820 SX_CTRL0 — SX control register0
  [16:15] SX_GPLL_REFCLK_DRIVE — GPLL Reference clock drive strength selection
    0=min (Unspecified); 3=max (Unspecified)
  [14:12] SX_TDC_CTRL — TDC control register
    0=Off (Unspecified); 1=Bit1 (Unspecified); 2=Bit2 (Unspecified); 4=Bit3 (Unspecified); 7=On (Unspecified)
  [8] SX_DTC_EDGE_ALIGN — DTC edge align
    0=PhaseSelNative (Unspecified); 1=PhaseSelSampled (Unspecified)
  [7:4] SX_DTC_CTRL — DTC control register default 0100
    0=Off (Unspecified); 1=EnableBleed (Unspecified); 2=BypassMode (Unspecified); 4=DTCResetto127 (Unspecified); 8=spare (Unspecified); 15=allOn (Unspecified)
  [3] SX_DCO_IDAC_BYPASS — DCO amplitude control bypass
    0=NoEffect (Unspecified); 1=Override (Unspecified)
  [2:0] SX_DCO_AMP_VCO — Selection of DCO core amplitude calibration
    0=400mV_at_25C (Unspecified); 1=300mV (Unspecified); 2=400mV (Unspecified); 3=500mV (Unspecified)
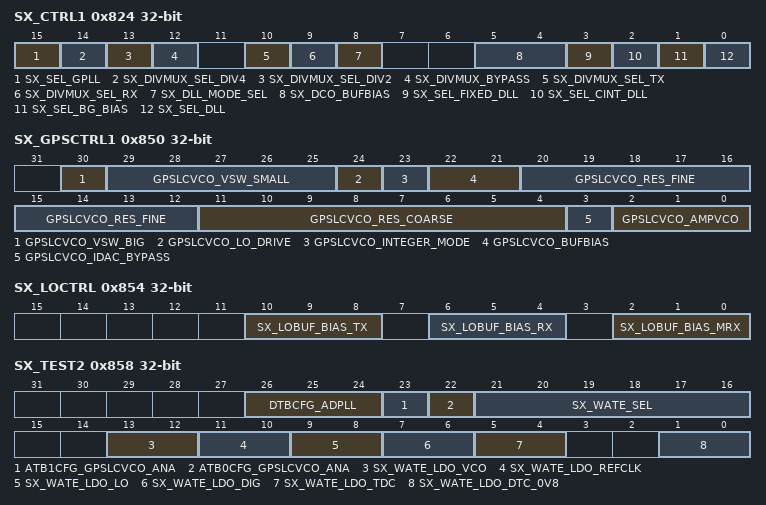
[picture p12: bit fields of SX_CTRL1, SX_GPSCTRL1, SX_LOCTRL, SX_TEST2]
0x824 SX_CTRL1 — SX control register1
  [15] SX_SEL_GPLL — Selection bit for GPS LO branch
    0=LO_from_LCVCO_disabled (Unspecified); 1=LO_from_LCVCO_enabled (Unspecified)
  [14] SX_DIVMUX_SEL_DIV4 — Selection bit for the DIV4 branch
    1=Enable (Unspecified); 0=NoEffect (Unspecified)
  [13] SX_DIVMUX_SEL_DIV2 — Selection bit for the DIV2 branch
    1=Enable (Unspecified); 0=NoEffect (Unspecified)
  [12] SX_DIVMUX_BYPASS — Selection bit for the bypass branch
    1=Enable (Unspecified); 0=NoEffect (Unspecified)
  [10] SX_DIVMUX_SEL_TX — Selection bit for the TX output branch
    1=Enable (Unspecified); 0=NoEffect (Unspecified)
  [9] SX_DIVMUX_SEL_RX — Selection bit for the RX output branch
    1=Enable (Unspecified); 0=NoEffect (Unspecified)
  [8] SX_DLL_MODE_SEL — Selection bit for the DLL MODE
    1=DLLselected (Unspecified); 0=NoEffect (Unspecified)
  [5:4] SX_DCO_BUFBIAS — VCO output buffer voltage swing selection
    0=min (Unspecified); 3=max (Unspecified)
  [3] SX_SEL_FIXED_DLL — Additional parallel stages in delay line of DLL
    1=Selected (Unspecified); 0=NoEffect (Unspecified)
  [2] SX_SEL_CINT_DLL — DLL CP internal filtering capacitor
    1=Selected (Unspecified); 0=NoEffect (Unspecified)
  [1] SX_SEL_BG_BIAS — Backgate bias selection for the delay line inverters of the DLL
    1=Inverted (PMOStoAVDD_NMOStoAVSS); 0=NoEffect (PMOStoAVSS_NMOStoAVDD)
  [0] SX_SEL_DLL — Selection bit for DLL
    1=Enable (Unspecified); 0=NoEffect (Unspecified)
0x838 SX_FS_CTRL — SX_FS registers
  [0] FS_PA_POWERED — Indication to ADPLL that PA is powered
    0=Low (Unspecified); 1=High (Unspecified)
0x83C SX_FS_START
  [0] FS_START — Start AdPll
    0=NoEffect (Unspecified); 1=Enabled (Unspecified)
0x850 SX_GPSCTRL1 — SX GPSLCVCO control register 1
  [30] GPSLCVCO_VSW_BIG — GPSLCVCO big capacitance bank control
    0=upperfreqs (Unspecified); 1=lowerfreqs (Unspecified)
  [29:25] GPSLCVCO_VSW_SMALL — GPSLCVCO small capacitance tuning bank control
    0=Maxfreq (Unspecified); 31=MinFreq (Unspecified)
  [24] GPSLCVCO_LO_DRIVE — GPSLCVCO LO buffer drive spare
    0=min (Unspecified); 1=max (Unspecified)
  [23] GPSLCVCO_INTEGER_MODE
    0=Fractional (Unspecified); 1=Integer (Unspecified)
  [22:21] GPSLCVCO_BUFBIAS — GPLCVCO isolation buffer bias
    0=Minimum (Unspecified); 3=Maximum (Unspecified)
  [20:12] GPSLCVCO_RES_FINE — Amplitude CTRL fine tuning
    0=Minimum (Unspecified); 0x1FF=Maximum (Unspecified)
  [11:4] GPSLCVCO_RES_COARSE — Amplitude CTRL coarse tuning
    0=Minimum (Unspecified); 255=Maximum (Unspecified)
  [3] GPSLCVCO_IDAC_BYPASS — GPLCVCO amplitude control bypass
    1=Selected (Unspecified); 0=NoEffect (Unspecified)
  [2:0] GPSLCVCO_AMPVCO — GPSLCVCO amplitude control register
    0=Minimum (Unspecified); 7=Maximum (Unspecified)
0x854 SX_LOCTRL — SX LO control register
  [all] fields
    0=min (Unspecified); 7=max (Unspecified)
  [10:8] SX_LOBUF_BIAS_TX — LO Line buffer biasing for the TX line
  [6:4] SX_LOBUF_BIAS_RX — LO Line buffer biasing for the RX line
  [2:0] SX_LOBUF_BIAS_MRX — LO Line buffer biasing for the MRX line
0x858 SX_TEST2
  [26:24] DTBCFG_ADPLL — DTB Enable control
    0=disconnected (TDC testclocks to DTB outputs); 1=TDC_DTB_all_Enable (Unspecified); 2=TDC_DTB_0_Enable (Unspecified); 4=AdPllLockedSignal_to_DTB (Unspecified)
  [23] ATB1CFG_GPSLCVCO_ANA — Selection bits for VCO LDO testoutputs
    0=disconnected (No connection); 1=TBD (LDO output to WATB OUT0)
  [22] ATB0CFG_GPSLCVCO_ANA — Selection bits for GPSLCVCO ATB0
    0=disconnected (No connection); 1=LDO output to WATB OUT0
  [21:16] SX_WATE_SEL — Selection bits for testoutputs ??? Content not up to date
    1=TST_IBPS10UA_toWATB0 (TST_IBPS10UA to WATB OUT0); 2=AVSS_toWATB1 (AVSS to WATB OUT1); 4=CPOUT_EXT_toWATB0 (CPOUT_EXT to WATB OUT0); 8=C2OUT_EXT_toWATB1 (C2OUT_EXT to WATB OUT1); 16=VAMPL_DET_toWATB0 (VAMPL_DET to WATB OUT0); 32=VREF_DET_toWATB1 (VREF_DET to WATB OUT1)
  [13:12] SX_WATE_LDO_VCO — Selection bits for VCO LDO testoutputs
    0=disconnected (No connection); 1=LDO output to WATB OUT0; 2=AVSS_VCO (AVSS_VCO to WATB OUT1)
  [11:10] SX_WATE_LDO_REFCLK — Selection bits for REFCLK LDO testoutputs
    0=disconnected (No connection); 1=LDO output to WATB OUT0; 2=LDO input to WATB OUT1
  [9:8] SX_WATE_LDO_LO — Selection bits for LO LDO testoutputs
    values as SX_WATE_LDO_REFCLK
  [7:6] SX_WATE_LDO_DIG — Selection bits for DIG LDO testoutputs
    values as SX_WATE_LDO_REFCLK
  [5:4] SX_WATE_LDO_TDC — Selection bits for TDC LDO testoutputs
    values as SX_WATE_LDO_REFCLK
  [1:0] SX_WATE_LDO_DTC_0V8 — Selection bits for DTC LDO testoutputs
    values as SX_WATE_LDO_REFCLK
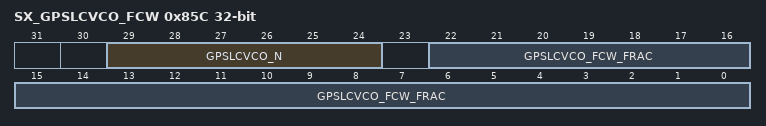
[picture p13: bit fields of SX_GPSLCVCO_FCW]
0x85C SX_GPSLCVCO_FCW
  [29:24] GPSLCVCO_N — Integer part of the Frequency control word
    0=minFreq (Unspecified)
  [22:0] GPSLCVCO_FCW_FRAC — Fractional part of the Frequency control word
    0=minFreq (Unspecified)
0x860 SX_GPSLCVCO_SWRESET
  [0] GPSLCVCO_ARSTSD — General asynchronous reset
    1=Reset (Unspecified); 0=NoReset (Unspecified)
0x864 SX_GPSLCVCO_SPARE
  [3:0] GPSLCVCO_SPARE — Spare
0x868 STROBE_SX_GPSLCVCO_FCWUPDREQ wo — SX GPSLCVCO FCW request
  [0] GPSLCVCO_FCW_UPDATE — Allow the taking into account the new fcw words
    0=NoEffect (Active on rising edge); 1=Request (Unspecified)
0xB08 SX_GPSLCVCO_READ ro
  [0] GPSLCVCO_AMP_OVER_T — GPSLCVCO VCO amplitude detector output
